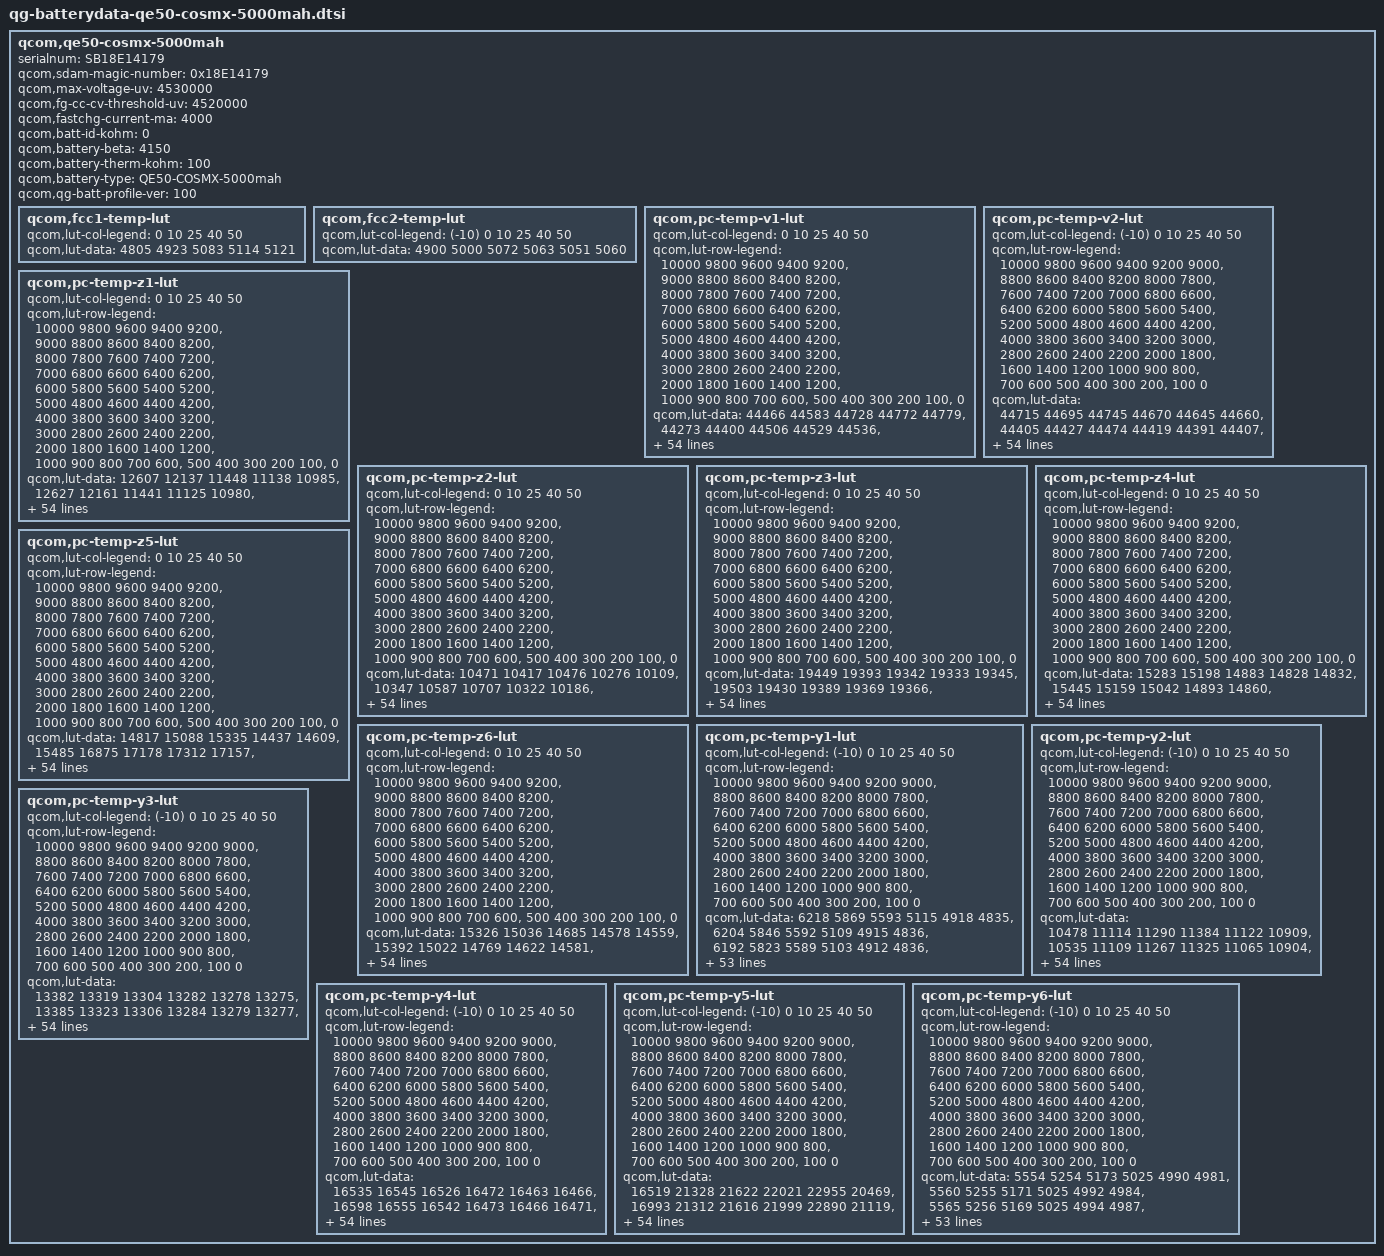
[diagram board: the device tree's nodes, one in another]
/* Copyright (c) 2018, The Linux Foundation. All rights reserved.
 *
 * This program is free software; you can redistribute it and/or modify
 * it under the terms of the GNU General Public License version 2 and
 * only version 2 as published by the Free Software Foundation.
 *
 * This program is distributed in the hope that it will be useful,
 * but WITHOUT ANY WARRANTY; without even the implied warranty of
 * MERCHANTABILITY or FITNESS FOR A PARTICULAR PURPOSE.  See the
 * GNU General Public License for more details.
 */
qcom,qe50-cosmx-5000mah {
    /* 6988537_Huaqin_QN6982A_COSMX_5000mAH_PM7250B_averaged_MasterSlave_Feb12th2024 */
    serialnum = "SB18E14179";
    qcom,sdam-magic-number = <0x18E14179>;
    qcom,max-voltage-uv = <4530000>;
    qcom,fg-cc-cv-threshold-uv = <4520000>;
    qcom,fastchg-current-ma = <4000>;
    qcom,batt-id-kohm = <0>;
    qcom,battery-beta = <4150>;
    qcom,battery-therm-kohm = <100>;
    qcom,battery-type = "QE50-COSMX-5000mah";
    qcom,qg-batt-profile-ver = <100>;

	qcom,fcc1-temp-lut {
		qcom,lut-col-legend = <0 10 25 40 50>;
		qcom,lut-data = <4805 4923 5083 5114 5121>;
	};

	qcom,fcc2-temp-lut {
		qcom,lut-col-legend = <(-10) 0 10 25 40 50>;
		qcom,lut-data = <4900 5000 5072 5063 5051 5060>;
	};

	qcom,pc-temp-v1-lut {
		qcom,lut-col-legend = <0 10 25 40 50>;
		qcom,lut-row-legend = <10000 9800 9600 9400 9200>,
			<9000 8800 8600 8400 8200>,
			<8000 7800 7600 7400 7200>,
			<7000 6800 6600 6400 6200>,
			<6000 5800 5600 5400 5200>,
			<5000 4800 4600 4400 4200>,
			<4000 3800 3600 3400 3200>,
			<3000 2800 2600 2400 2200>,
			<2000 1800 1600 1400 1200>,
			<1000 900 800 700 600>,
			<500 400 300 200 100>,
			<0>;
		qcom,lut-data = <44466 44583 44728 44772 44779>,
			<44273 44400 44506 44529 44536>,
			<44081 44215 44321 44338 44339>,
			<43884 44029 44142 44157 44160>,
			<43678 43837 43950 43967 43971>,
			<43463 43632 43749 43767 43770>,
			<43239 43415 43536 43558 43562>,
			<43004 43189 43309 43337 43343>,
			<42764 42953 43073 43106 43114>,
			<42524 42711 42829 42866 42877>,
			<42282 42470 42578 42616 42630>,
			<42044 42229 42328 42365 42381>,
			<41813 41988 42079 42114 42132>,
			<41586 41747 41834 41864 41883>,
			<41364 41511 41593 41621 41640>,
			<41146 41285 41357 41382 41400>,
			<40934 41065 41129 41150 41168>,
			<40729 40856 40908 40927 40943>,
			<40532 40663 40698 40712 40726>,
			<40337 40477 40507 40513 40522>,
			<40153 40271 40322 40323 40330>,
			<39962 40024 40095 40099 40110>,
			<39731 39761 39796 39801 39826>,
			<39451 39496 39523 39527 39561>,
			<39217 39256 39328 39353 39384>,
			<39061 39100 39168 39215 39242>,
			<38935 38992 39039 39075 39097>,
			<38830 38896 38929 38929 38944>,
			<38740 38795 38826 38798 38807>,
			<38660 38696 38725 38692 38695>,
			<38582 38603 38630 38599 38597>,
			<38509 38516 38539 38511 38505>,
			<38441 38434 38451 38428 38420>,
			<38378 38360 38370 38350 38340>,
			<38321 38292 38298 38279 38266>,
			<38272 38231 38230 38210 38193>,
			<38231 38180 38163 38138 38117>,
			<38184 38128 38099 38061 38039>,
			<38118 38061 38022 37969 37944>,
			<38036 37978 37922 37842 37811>,
			<37936 37879 37809 37704 37664>,
			<37810 37755 37685 37582 37529>,
			<37667 37613 37545 37457 37394>,
			<37503 37449 37376 37284 37213>,
			<37337 37290 37224 37144 37072>,
			<37208 37162 37120 37064 37005>,
			<37171 37119 37087 37033 36980>,
			<37128 37090 37062 37010 36955>,
			<37092 37057 37040 36985 36927>,
			<37055 37015 36986 36914 36853>,
			<36969 36864 36749 36627 36557>,
			<36666 36563 36297 36166 36104>,
			<36146 36051 35700 35563 35512>,
			<35447 35325 34888 34736 34700>,
			<34308 34189 33628 33437 33444>,
			<30000 30000 30000 30000 30000>;
	};

	qcom,pc-temp-v2-lut {
		qcom,lut-col-legend = <(-10) 0 10 25 40 50>;
		qcom,lut-row-legend = <10000 9800 9600 9400 9200 9000>,
			<8800 8600 8400 8200 8000 7800>,
			<7600 7400 7200 7000 6800 6600>,
			<6400 6200 6000 5800 5600 5400>,
			<5200 5000 4800 4600 4400 4200>,
			<4000 3800 3600 3400 3200 3000>,
			<2800 2600 2400 2200 2000 1800>,
			<1600 1400 1200 1000 900 800>,
			<700 600 500 400 300 200>,
			<100 0>;
		qcom,lut-data = <44715 44695 44745 44670 44645 44660>,
			<44405 44427 44474 44419 44391 44407>,
			<44130 44181 44229 44184 44153 44172>,
			<43894 43963 44017 43968 43936 43959>,
			<43697 43771 43836 43769 43739 43769>,
			<43504 43575 43649 43566 43537 43573>,
			<43294 43363 43442 43348 43321 43360>,
			<43078 43141 43223 43121 43096 43137>,
			<42855 42909 42995 42886 42863 42905>,
			<42622 42665 42755 42640 42619 42662>,
			<42387 42419 42512 42391 42372 42415>,
			<42153 42174 42267 42142 42125 42166>,
			<41919 41930 42020 41891 41877 41916>,
			<41679 41692 41776 41646 41633 41671>,
			<41433 41458 41534 41405 41394 41431>,
			<41182 41228 41298 41170 41160 41197>,
			<40920 41009 41069 40941 40933 40968>,
			<40648 40789 40847 40720 40714 40748>,
			<40382 40539 40638 40512 40509 40539>,
			<40124 40254 40434 40314 40314 40339>,
			<39877 39975 40197 40094 40107 40133>,
			<39647 39715 39901 39834 39878 39921>,
			<39432 39472 39611 39572 39642 39701>,
			<39232 39262 39374 39338 39403 39456>,
			<39045 39078 39168 39122 39163 39201>,
			<38872 38913 38990 38944 38970 39002>,
			<38715 38762 38834 38801 38821 38854>,
			<38571 38624 38694 38674 38692 38726>,
			<38437 38497 38563 38553 38574 38602>,
			<38307 38379 38444 38441 38468 38489>,
			<38185 38270 38337 38338 38371 38386>,
			<38087 38166 38237 38242 38283 38294>,
			<38008 38070 38142 38154 38199 38207>,
			<37937 37984 38051 38075 38115 38124>,
			<37866 37908 37964 38000 38032 38041>,
			<37798 37839 37884 37920 37939 37942>,
			<37728 37778 37813 37834 37836 37820>,
			<37657 37720 37741 37743 37728 37699>,
			<37582 37652 37666 37644 37627 37594>,
			<37496 37575 37585 37538 37525 37492>,
			<37401 37483 37487 37435 37422 37388>,
			<37303 37361 37371 37330 37317 37279>,
			<37202 37217 37229 37196 37184 37133>,
			<37104 37056 37076 37042 37025 36968>,
			<37012 36918 36928 36932 36928 36878>,
			<36919 36812 36823 36880 36877 36826>,
			<36870 36764 36782 36866 36864 36812>,
			<36822 36721 36740 36847 36847 36794>,
			<36775 36674 36678 36808 36818 36763>,
			<36721 36612 36561 36685 36735 36665>,
			<36653 36485 36324 36340 36427 36332>,
			<36569 36143 35924 35797 35929 35826>,
			<36457 35526 35311 35071 35276 35159>,
			<36069 34533 34461 34019 34366 34223>,
			<35516 33478 33260 32501 32956 32853>,
			<35225 31991 29998 28746 28131 29180>;
	};

	qcom,pc-temp-z1-lut {
		qcom,lut-col-legend = <0 10 25 40 50>;
		qcom,lut-row-legend = <10000 9800 9600 9400 9200>,
			<9000 8800 8600 8400 8200>,
			<8000 7800 7600 7400 7200>,
			<7000 6800 6600 6400 6200>,
			<6000 5800 5600 5400 5200>,
			<5000 4800 4600 4400 4200>,
			<4000 3800 3600 3400 3200>,
			<3000 2800 2600 2400 2200>,
			<2000 1800 1600 1400 1200>,
			<1000 900 800 700 600>,
			<500 400 300 200 100>,
			<0>;
		qcom,lut-data = <12607 12137 11448 11138 10985>,
			<12627 12161 11441 11125 10980>,
			<12638 12164 11428 11113 10972>,
			<12644 12144 11418 11101 10964>,
			<12633 12119 11405 11090 10956>,
			<12600 12105 11391 11079 10948>,
			<12570 12096 11376 11069 10940>,
			<12540 12083 11361 11060 10934>,
			<12511 12059 11346 11052 10928>,
			<12496 12035 11333 11045 10924>,
			<12483 12018 11322 11040 10921>,
			<12470 12006 11315 11036 10918>,
			<12452 11997 11311 11033 10916>,
			<12431 11993 11308 11030 10914>,
			<12415 11990 11307 11029 10913>,
			<12402 11987 11307 11028 10913>,
			<12394 11983 11307 11027 10912>,
			<12395 11980 11307 11030 10912>,
			<12401 11981 11307 11033 10912>,
			<12407 11984 11310 11032 10912>,
			<12419 11985 11314 11029 10913>,
			<12430 11986 11314 11028 10913>,
			<12434 11986 11312 11027 10912>,
			<12434 11988 11311 11026 10911>,
			<12433 11993 11312 11026 10911>,
			<12431 11999 11316 11028 10913>,
			<12427 12007 11320 11030 10914>,
			<12429 12013 11329 11033 10916>,
			<12435 12014 11336 11036 10918>,
			<12441 12015 11341 11039 10920>,
			<12448 12018 11345 11042 10923>,
			<12459 12027 11349 11046 10926>,
			<12468 12036 11354 11049 10930>,
			<12476 12041 11361 11054 10933>,
			<12484 12045 11369 11059 10937>,
			<12487 12050 11379 11065 10941>,
			<12485 12062 11388 11071 10945>,
			<12485 12074 11397 11078 10950>,
			<12497 12083 11406 11084 10955>,
			<12516 12090 11416 11091 10959>,
			<12537 12099 11424 11097 10964>,
			<12563 12112 11434 11103 10968>,
			<12572 12123 11443 11108 10973>,
			<12564 12120 11453 11113 10977>,
			<12585 12133 11464 11120 10981>,
			<12604 12149 11468 11124 10984>,
			<12600 12164 11476 11124 10984>,
			<12585 12158 11480 11124 10984>,
			<12600 12160 11491 11129 10988>,
			<12595 12168 11489 11137 10993>,
			<12635 12163 11489 11142 10997>,
			<12627 12185 11495 11146 11002>,
			<12649 12192 11517 11157 11011>,
			<12658 12216 11526 11169 11022>,
			<12658 12216 11526 11169 11022>,
			<12658 12216 11526 11169 11022>;
	};

	qcom,pc-temp-z2-lut {
		qcom,lut-col-legend = <0 10 25 40 50>;
		qcom,lut-row-legend = <10000 9800 9600 9400 9200>,
			<9000 8800 8600 8400 8200>,
			<8000 7800 7600 7400 7200>,
			<7000 6800 6600 6400 6200>,
			<6000 5800 5600 5400 5200>,
			<5000 4800 4600 4400 4200>,
			<4000 3800 3600 3400 3200>,
			<3000 2800 2600 2400 2200>,
			<2000 1800 1600 1400 1200>,
			<1000 900 800 700 600>,
			<500 400 300 200 100>,
			<0>;
		qcom,lut-data = <10471 10417 10476 10276 10109>,
			<10347 10587 10707 10322 10186>,
			<10430 10650 10721 10488 10390>,
			<10503 10643 10716 10564 10487>,
			<10496 10615 10685 10572 10502>,
			<10463 10577 10615 10514 10453>,
			<10431 10536 10548 10440 10385>,
			<10402 10504 10484 10365 10311>,
			<10374 10467 10426 10293 10236>,
			<10353 10434 10391 10265 10202>,
			<10334 10562 10366 10251 10185>,
			<10320 10809 10358 10247 10176>,
			<10309 10845 10355 10258 10175>,
			<10300 10612 10354 10274 10177>,
			<10300 10419 10356 10277 10173>,
			<10315 10420 10362 10265 10166>,
			<10334 10427 10371 10260 10160>,
			<10344 10449 10387 10278 10135>,
			<10352 10698 10411 10298 10106>,
			<10363 10953 10676 10276 10115>,
			<10378 10888 11224 10215 10147>,
			<10398 10642 12118 10203 10165>,
			<10427 10542 13715 10308 10171>,
			<10472 10540 14442 10399 10178>,
			<10497 10513 12658 10340 10190>,
			<10494 10494 10447 10219 10212>,
			<10488 10480 10208 10286 10299>,
			<10480 10472 10249 10959 10724>,
			<10467 10477 10296 11434 11029>,
			<10457 10485 10344 11221 10872>,
			<10453 10487 10394 10825 10562>,
			<10451 10484 10443 10609 10375>,
			<10451 10480 10504 10480 10250>,
			<10457 10485 10527 10361 10153>,
			<10465 10500 10495 10208 10062>,
			<10466 10510 10459 10093 9999>,
			<10465 10512 10457 10092 10009>,
			<10463 10515 10461 10134 10077>,
			<10466 10519 10471 10186 10150>,
			<10469 10526 10513 10262 10226>,
			<10466 10533 10558 10330 10290>,
			<10446 10538 10580 10361 10316>,
			<10423 10540 10595 10392 10335>,
			<10399 10516 10603 10534 10463>,
			<10496 10551 10588 10553 10484>,
			<10507 10553 10525 10336 10263>,
			<10473 10543 10460 10326 10220>,
			<10468 10536 10456 10332 10239>,
			<10472 10546 10461 10360 10239>,
			<10404 10592 10548 10420 10319>,
			<10379 10573 10535 10347 10282>,
			<10255 10541 10474 10135 10006>,
			<10112 10356 10394 10049 9942>,
			<9981 10323 10301 9982 9890>,
			<9981 10323 10301 9982 9890>,
			<9981 10323 10301 9982 9890>;
	};

	qcom,pc-temp-z3-lut {
		qcom,lut-col-legend = <0 10 25 40 50>;
		qcom,lut-row-legend = <10000 9800 9600 9400 9200>,
			<9000 8800 8600 8400 8200>,
			<8000 7800 7600 7400 7200>,
			<7000 6800 6600 6400 6200>,
			<6000 5800 5600 5400 5200>,
			<5000 4800 4600 4400 4200>,
			<4000 3800 3600 3400 3200>,
			<3000 2800 2600 2400 2200>,
			<2000 1800 1600 1400 1200>,
			<1000 900 800 700 600>,
			<500 400 300 200 100>,
			<0>;
		qcom,lut-data = <19449 19393 19342 19333 19345>,
			<19503 19430 19389 19369 19366>,
			<19526 19450 19402 19387 19390>,
			<19541 19458 19409 19398 19397>,
			<19551 19462 19417 19408 19404>,
			<19559 19466 19425 19417 19414>,
			<19562 19469 19432 19422 19419>,
			<19563 19471 19438 19424 19420>,
			<19563 19470 19441 19425 19421>,
			<19562 19469 19440 19424 19420>,
			<19560 19474 19437 19419 19415>,
			<19557 19481 19433 19415 19410>,
			<19551 19481 19426 19411 19406>,
			<19543 19468 19418 19408 19403>,
			<19537 19455 19413 19404 19399>,
			<19531 19450 19410 19400 19395>,
			<19527 19447 19405 19395 19391>,
			<19523 19446 19401 19390 19386>,
			<19519 19447 19398 19384 19381>,
			<19516 19448 19395 19378 19376>,
			<19514 19446 19392 19373 19370>,
			<19512 19448 19390 19370 19366>,
			<19516 19454 19390 19370 19363>,
			<19531 19455 19391 19370 19360>,
			<19541 19452 19384 19360 19351>,
			<19539 19446 19372 19342 19340>,
			<19534 19439 19368 19346 19345>,
			<19529 19435 19367 19407 19404>,
			<19525 19435 19367 19450 19448>,
			<19521 19437 19369 19445 19444>,
			<19519 19439 19374 19434 19434>,
			<19517 19442 19381 19424 19424>,
			<19517 19445 19394 19415 19414>,
			<19517 19446 19400 19405 19404>,
			<19518 19446 19398 19391 19392>,
			<19517 19446 19395 19378 19379>,
			<19515 19443 19391 19367 19368>,
			<19513 19440 19383 19358 19358>,
			<19510 19436 19378 19355 19350>,
			<19506 19432 19377 19355 19345>,
			<19502 19429 19376 19356 19342>,
			<19498 19426 19373 19357 19347>,
			<19493 19423 19370 19357 19360>,
			<19485 19420 19369 19363 19367>,
			<19450 19407 19365 19363 19368>,
			<19419 19401 19356 19349 19358>,
			<19353 19396 19350 19341 19347>,
			<19348 19366 19348 19331 19332>,
			<19323 19359 19340 19328 19325>,
			<19294 19335 19333 19325 19323>,
			<19296 19336 19343 19338 19331>,
			<19306 19337 19363 19365 19356>,
			<19348 19366 19371 19366 19356>,
			<19402 19387 19372 19367 19356>,
			<19402 19387 19372 19367 19356>,
			<19402 19387 19372 19367 19356>;
	};

	qcom,pc-temp-z4-lut {
		qcom,lut-col-legend = <0 10 25 40 50>;
		qcom,lut-row-legend = <10000 9800 9600 9400 9200>,
			<9000 8800 8600 8400 8200>,
			<8000 7800 7600 7400 7200>,
			<7000 6800 6600 6400 6200>,
			<6000 5800 5600 5400 5200>,
			<5000 4800 4600 4400 4200>,
			<4000 3800 3600 3400 3200>,
			<3000 2800 2600 2400 2200>,
			<2000 1800 1600 1400 1200>,
			<1000 900 800 700 600>,
			<500 400 300 200 100>,
			<0>;
		qcom,lut-data = <15283 15198 14883 14828 14832>,
			<15445 15159 15042 14893 14860>,
			<15336 15106 15012 14900 14881>,
			<15201 15032 14952 14871 14860>,
			<15110 14961 14908 14845 14840>,
			<15030 14907 14870 14821 14823>,
			<14967 14863 14836 14799 14805>,
			<14917 14829 14806 14779 14787>,
			<14876 14802 14780 14762 14769>,
			<14842 14777 14757 14749 14759>,
			<14813 14743 14737 14739 14753>,
			<14789 14707 14726 14732 14750>,
			<14771 14694 14721 14729 14748>,
			<14756 14702 14716 14726 14746>,
			<14744 14708 14711 14722 14744>,
			<14734 14706 14705 14719 14742>,
			<14727 14703 14700 14716 14739>,
			<14723 14698 14697 14713 14738>,
			<14720 14683 14693 14710 14736>,
			<14718 14668 14680 14706 14733>,
			<14716 14669 14667 14701 14728>,
			<14715 14698 14674 14705 14730>,
			<14727 14738 14737 14769 14788>,
			<14778 14786 14799 14831 14846>,
			<14811 14831 14832 14846 14853>,
			<14813 14838 14855 14854 14855>,
			<14814 14823 14855 14845 14845>,
			<14813 14803 14841 14770 14775>,
			<14802 14785 14823 14713 14720>,
			<14787 14768 14805 14708 14715>,
			<14777 14752 14785 14705 14713>,
			<14768 14738 14763 14702 14709>,
			<14761 14727 14738 14697 14705>,
			<14756 14719 14720 14693 14700>,
			<14751 14714 14707 14688 14693>,
			<14745 14710 14698 14683 14685>,
			<14738 14707 14693 14679 14680>,
			<14731 14704 14689 14674 14676>,
			<14723 14702 14689 14674 14676>,
			<14714 14700 14694 14690 14698>,
			<14706 14697 14700 14706 14721>,
			<14699 14692 14700 14703 14715>,
			<14691 14683 14698 14695 14700>,
			<14681 14673 14697 14698 14706>,
			<14670 14655 14686 14691 14702>,
			<14694 14650 14668 14669 14666>,
			<14761 14648 14665 14670 14667>,
			<14766 14672 14652 14661 14663>,
			<14791 14670 14638 14637 14640>,
			<14819 14690 14633 14623 14622>,
			<14812 14692 14650 14664 14680>,
			<14810 14699 14656 14668 14692>,
			<14785 14685 14657 14677 14703>,
			<14758 14683 14662 14684 14712>,
			<14758 14683 14662 14684 14712>,
			<14758 14683 14662 14684 14712>;
	};

	qcom,pc-temp-z5-lut {
		qcom,lut-col-legend = <0 10 25 40 50>;
		qcom,lut-row-legend = <10000 9800 9600 9400 9200>,
			<9000 8800 8600 8400 8200>,
			<8000 7800 7600 7400 7200>,
			<7000 6800 6600 6400 6200>,
			<6000 5800 5600 5400 5200>,
			<5000 4800 4600 4400 4200>,
			<4000 3800 3600 3400 3200>,
			<3000 2800 2600 2400 2200>,
			<2000 1800 1600 1400 1200>,
			<1000 900 800 700 600>,
			<500 400 300 200 100>,
			<0>;
		qcom,lut-data = <14817 15088 15335 14437 14609>,
			<15485 16875 17178 17312 17157>,
			<16266 18009 17763 18654 19669>,
			<17073 18616 18261 19938 20936>,
			<17857 19094 18813 21207 22267>,
			<18655 19682 19482 22432 23768>,
			<19472 20439 20319 23534 25059>,
			<20292 21181 21400 24471 26102>,
			<21141 21768 22617 25340 27018>,
			<22115 22456 24153 26272 27614>,
			<23289 25422 25868 27272 28006>,
			<24251 29985 26458 28170 28338>,
			<24794 31297 26490 28863 28629>,
			<25257 29376 26531 29526 28922>,
			<25984 27774 27053 30393 29367>,
			<27235 28268 28346 31451 30021>,
			<28481 29254 29565 32488 30715>,
			<29256 30374 30774 33469 31363>,
			<29862 32958 31989 34449 32088>,
			<30680 35326 33730 35595 33238>,
			<31786 35341 35302 36790 34728>,
			<33480 41278 35500 37032 35074>,
			<38622 49089 37796 35323 32487>,
			<51557 48772 39178 32403 28483>,
			<59272 41972 33601 26588 23503>,
			<55243 35902 24679 18874 17940>,
			<47496 30271 21199 18971 18316>,
			<42336 26730 19802 32349 31989>,
			<38562 26442 19326 41815 42219>,
			<36244 26597 19430 40756 42060>,
			<35709 27159 19715 38798 41613>,
			<35410 29274 20941 37920 41388>,
			<35359 32188 24640 37501 41081>,
			<36283 35170 28195 36930 40550>,
			<37726 38443 31250 34233 38963>,
			<38807 40377 33677 31343 36753>,
			<39727 41375 34802 31104 34938>,
			<40801 41926 35504 31333 33156>,
			<42710 41871 36063 31834 31558>,
			<44729 41632 36620 34984 29886>,
			<44970 41518 36945 38039 28780>,
			<42884 40866 34384 34873 28970>,
			<40080 40302 29925 28676 29944>,
			<36186 40736 30356 32586 34915>,
			<30613 40845 30602 34172 38142>,
			<25492 38260 28669 26302 31802>,
			<13773 34698 25727 21800 22975>,
			<13416 22870 26656 20025 18837>,
			<12532 20683 25316 23388 21310>,
			<11879 14950 24071 28332 29982>,
			<11982 15095 26102 26005 24195>,
			<12273 15255 24973 24282 20415>,
			<13051 18307 25188 20904 17432>,
			<15578 22175 22455 17955 15234>,
			<15578 22175 22455 17955 15234>,
			<15578 22175 22455 17955 15234>;
	};

	qcom,pc-temp-z6-lut {
		qcom,lut-col-legend = <0 10 25 40 50>;
		qcom,lut-row-legend = <10000 9800 9600 9400 9200>,
			<9000 8800 8600 8400 8200>,
			<8000 7800 7600 7400 7200>,
			<7000 6800 6600 6400 6200>,
			<6000 5800 5600 5400 5200>,
			<5000 4800 4600 4400 4200>,
			<4000 3800 3600 3400 3200>,
			<3000 2800 2600 2400 2200>,
			<2000 1800 1600 1400 1200>,
			<1000 900 800 700 600>,
			<500 400 300 200 100>,
			<0>;
		qcom,lut-data = <15326 15036 14685 14578 14559>,
			<15392 15022 14769 14622 14581>,
			<15333 14998 14756 14629 14598>,
			<15259 14960 14730 14622 14594>,
			<15205 14919 14710 14615 14590>,
			<15156 14888 14694 14608 14586>,
			<15114 14862 14679 14601 14581>,
			<15079 14840 14666 14593 14575>,
			<15048 14820 14653 14584 14567>,
			<15021 14802 14640 14577 14561>,
			<14996 14786 14628 14569 14555>,
			<14975 14770 14618 14563 14550>,
			<14955 14760 14610 14559 14547>,
			<14938 14753 14604 14555 14544>,
			<14925 14748 14598 14551 14540>,
			<14915 14744 14593 14546 14536>,
			<14908 14740 14589 14542 14532>,
			<14904 14736 14585 14537 14528>,
			<14901 14731 14581 14533 14524>,
			<14900 14726 14575 14527 14519>,
			<14901 14726 14569 14522 14514>,
			<14901 14740 14572 14522 14513>,
			<14910 14759 14602 14551 14536>,
			<14940 14779 14628 14577 14558>,
			<14960 14798 14636 14575 14557>,
			<14961 14800 14639 14571 14553>,
			<14961 14792 14636 14570 14552>,
			<14961 14782 14631 14571 14553>,
			<14956 14776 14626 14571 14554>,
			<14950 14771 14621 14568 14551>,
			<14946 14768 14615 14560 14545>,
			<14944 14765 14612 14554 14539>,
			<14943 14763 14609 14548 14533>,
			<14944 14763 14606 14542 14526>,
			<14945 14763 14602 14533 14517>,
			<14945 14763 14598 14525 14508>,
			<14945 14763 14594 14518 14500>,
			<14946 14763 14591 14512 14492>,
			<14947 14764 14590 14510 14489>,
			<14949 14765 14593 14518 14495>,
			<14951 14766 14597 14526 14502>,
			<14954 14767 14598 14525 14504>,
			<14958 14767 14598 14523 14505>,
			<14962 14766 14600 14528 14511>,
			<14955 14761 14597 14526 14511>,
			<14955 14759 14587 14510 14490>,
			<14951 14757 14584 14507 14485>,
			<14951 14753 14579 14498 14476>,
			<14954 14750 14570 14486 14463>,
			<14953 14752 14567 14479 14454>,
			<14958 14757 14580 14504 14483>,
			<14975 14767 14596 14523 14506>,
			<14993 14784 14605 14530 14515>,
			<15020 14804 14613 14538 14523>,
			<15020 14804 14613 14538 14523>,
			<15020 14804 14613 14538 14523>;
	};

	qcom,pc-temp-y1-lut {
		qcom,lut-col-legend = <(-10) 0 10 25 40 50>;
		qcom,lut-row-legend = <10000 9800 9600 9400 9200 9000>,
			<8800 8600 8400 8200 8000 7800>,
			<7600 7400 7200 7000 6800 6600>,
			<6400 6200 6000 5800 5600 5400>,
			<5200 5000 4800 4600 4400 4200>,
			<4000 3800 3600 3400 3200 3000>,
			<2800 2600 2400 2200 2000 1800>,
			<1600 1400 1200 1000 900 800>,
			<700 600 500 400 300 200>,
			<100 0>;
		qcom,lut-data = <6218 5869 5593 5115 4918 4835>,
			<6204 5846 5592 5109 4915 4836>,
			<6192 5823 5589 5103 4912 4836>,
			<6182 5801 5586 5098 4909 4835>,
			<6175 5785 5582 5092 4907 4833>,
			<6172 5777 5578 5088 4905 4831>,
			<6178 5778 5573 5084 4903 4827>,
			<6190 5781 5566 5080 4902 4823>,
			<6193 5780 5559 5076 4900 4821>,
			<6183 5772 5550 5073 4897 4820>,
			<6175 5767 5545 5070 4895 4820>,
			<6178 5765 5540 5068 4894 4819>,
			<6186 5763 5534 5067 4893 4818>,
			<6189 5762 5528 5065 4892 4817>,
			<6185 5767 5520 5063 4890 4816>,
			<6181 5769 5518 5061 4889 4815>,
			<6178 5766 5517 5061 4889 4815>,
			<6174 5762 5517 5061 4889 4814>,
			<6173 5763 5518 5061 4889 4814>,
			<6176 5766 5517 5062 4890 4815>,
			<6179 5769 5516 5062 4891 4815>,
			<6179 5774 5516 5064 4891 4816>,
			<6175 5778 5515 5065 4891 4817>,
			<6173 5778 5514 5067 4892 4817>,
			<6172 5774 5514 5070 4894 4818>,
			<6173 5772 5516 5073 4896 4819>,
			<6178 5777 5524 5076 4897 4820>,
			<6199 5784 5530 5078 4899 4821>,
			<6213 5784 5530 5080 4901 4823>,
			<6202 5779 5526 5082 4903 4824>,
			<6183 5776 5525 5085 4906 4826>,
			<6181 5779 5529 5088 4909 4828>,
			<6191 5783 5532 5091 4911 4830>,
			<6198 5786 5534 5095 4914 4832>,
			<6197 5785 5537 5099 4916 4834>,
			<6196 5785 5539 5103 4918 4836>,
			<6196 5790 5542 5108 4920 4837>,
			<6200 5798 5545 5112 4922 4839>,
			<6204 5802 5547 5114 4923 4840>,
			<6195 5804 5549 5116 4925 4842>,
			<6171 5806 5553 5118 4927 4842>,
			<6159 5800 5560 5123 4929 4843>,
			<6157 5796 5568 5127 4931 4844>,
			<6157 5790 5575 5132 4934 4848>,
			<6170 5786 5572 5135 4938 4851>,
			<6189 5803 5583 5140 4941 4853>,
			<6190 5820 5584 5142 4940 4852>,
			<6181 5809 5587 5143 4940 4852>,
			<6172 5802 5586 5143 4941 4854>,
			<6224 5797 5587 5141 4940 4855>,
			<6251 5857 5589 5145 4941 4856>,
			<6341 5932 5601 5151 4947 4860>,
			<6450 6137 5646 5166 4953 4866>,
			<6598 6252 5815 5179 4961 4875>,
			<6598 6252 5815 5179 4961 4875>,
			<6598 6252 5815 5179 4961 4875>;
	};

	qcom,pc-temp-y2-lut {
		qcom,lut-col-legend = <(-10) 0 10 25 40 50>;
		qcom,lut-row-legend = <10000 9800 9600 9400 9200 9000>,
			<8800 8600 8400 8200 8000 7800>,
			<7600 7400 7200 7000 6800 6600>,
			<6400 6200 6000 5800 5600 5400>,
			<5200 5000 4800 4600 4400 4200>,
			<4000 3800 3600 3400 3200 3000>,
			<2800 2600 2400 2200 2000 1800>,
			<1600 1400 1200 1000 900 800>,
			<700 600 500 400 300 200>,
			<100 0>;
		qcom,lut-data = <10478 11114 11290 11384 11122 10909>,
			<10535 11109 11267 11325 11065 10904>,
			<10606 11098 11241 11239 10991 10889>,
			<10679 11083 11211 11145 10915 10867>,
			<10740 11067 11180 11067 10852 10838>,
			<10778 11056 11147 11027 10815 10806>,
			<10792 11037 11105 11014 10798 10764>,
			<10800 11014 11067 11003 10784 10720>,
			<10811 11009 11050 10989 10765 10690>,
			<10824 11014 11039 10972 10737 10668>,
			<10839 11021 11036 10964 10711 10647>,
			<10863 11034 11042 10960 10687 10618>,
			<10895 11056 11052 10957 10668 10596>,
			<10923 11081 11066 10965 10675 10594>,
			<10951 11112 11095 10984 10713 10596>,
			<10973 11149 11133 11011 10752 10599>,
			<10981 11208 11186 11062 10781 10611>,
			<10986 11268 11249 11134 10816 10633>,
			<10987 11269 11326 11236 10875 10665>,
			<10981 11217 11413 11370 10972 10722>,
			<10971 11185 11432 11416 11078 10817>,
			<10965 11188 11341 11374 11228 11103>,
			<10961 11196 11260 11312 11341 11349>,
			<10954 11202 11256 11256 11280 11265>,
			<10941 11207 11265 11198 11098 11025>,
			<10923 11212 11274 11189 11031 10945>,
			<10908 11223 11284 11256 11047 10987>,
			<10895 11238 11288 11316 11074 11046>,
			<10873 11244 11286 11308 11118 11089>,
			<10603 11248 11290 11287 11180 11132>,
			<10133 11250 11309 11288 11204 11187>,
			<9921 11241 11340 11351 11194 11295>,
			<9834 11223 11351 11421 11185 11403>,
			<9779 11210 11330 11463 11256 11519>,
			<9748 11187 11313 11494 11406 11647>,
			<9727 11161 11312 11511 11446 11638>,
			<9712 11124 11304 11531 11389 11424>,
			<9700 11065 11283 11539 11318 11258>,
			<9692 10992 11225 11475 11257 11232>,
			<9684 10902 11165 11367 11202 11219>,
			<9678 10796 11127 11356 11198 11200>,
			<9673 10634 11082 11407 11238 11170>,
			<9670 10391 10956 11358 11223 11092>,
			<9667 9938 10831 11202 11062 10910>,
			<9663 9745 10613 11143 10904 10727>,
			<9660 9696 10357 11168 10827 10648>,
			<9658 9679 10267 11253 10886 10635>,
			<9657 9668 10165 11273 10884 10656>,
			<9655 9660 10027 11308 10920 10695>,
			<9652 9654 9893 11292 10920 10715>,
			<9650 9650 9778 11166 10778 10616>,
			<9648 9649 9684 11056 10722 10584>,
			<9648 9648 9659 10941 10627 10521>,
			<9648 9649 9656 10765 10509 10349>,
			<9648 9649 9656 10765 10509 10349>,
			<9648 9649 9656 10765 10509 10349>;
	};

	qcom,pc-temp-y3-lut {
		qcom,lut-col-legend = <(-10) 0 10 25 40 50>;
		qcom,lut-row-legend = <10000 9800 9600 9400 9200 9000>,
			<8800 8600 8400 8200 8000 7800>,
			<7600 7400 7200 7000 6800 6600>,
			<6400 6200 6000 5800 5600 5400>,
			<5200 5000 4800 4600 4400 4200>,
			<4000 3800 3600 3400 3200 3000>,
			<2800 2600 2400 2200 2000 1800>,
			<1600 1400 1200 1000 900 800>,
			<700 600 500 400 300 200>,
			<100 0>;
		qcom,lut-data = <13382 13319 13304 13282 13278 13275>,
			<13385 13323 13306 13284 13279 13277>,
			<13390 13328 13308 13285 13281 13279>,
			<13396 13331 13310 13287 13282 13281>,
			<13402 13335 13312 13288 13283 13283>,
			<13404 13337 13313 13290 13285 13284>,
			<13405 13339 13314 13291 13286 13285>,
			<13405 13340 13315 13292 13287 13286>,
			<13405 13340 13316 13293 13288 13287>,
			<13405 13340 13317 13295 13289 13288>,
			<13405 13339 13318 13296 13290 13289>,
			<13405 13338 13318 13296 13291 13289>,
			<13405 13337 13318 13297 13292 13290>,
			<13405 13337 13318 13297 13293 13291>,
			<13403 13336 13317 13298 13293 13291>,
			<13400 13336 13316 13298 13294 13292>,
			<13396 13337 13314 13299 13295 13294>,
			<13389 13339 13313 13299 13296 13295>,
			<13383 13339 13313 13298 13297 13296>,
			<13378 13334 13314 13296 13298 13297>,
			<13374 13329 13314 13294 13299 13298>,
			<13370 13325 13310 13292 13295 13295>,
			<13367 13322 13305 13291 13290 13291>,
			<13364 13320 13302 13289 13286 13287>,
			<13361 13318 13301 13286 13284 13283>,
			<13358 13317 13300 13285 13282 13282>,
			<13356 13316 13299 13285 13280 13284>,
			<13355 13316 13298 13285 13280 13285>,
			<13353 13315 13298 13284 13279 13285>,
			<13347 13315 13297 13283 13279 13284>,
			<13339 13315 13298 13283 13279 13283>,
			<13338 13314 13298 13283 13279 13282>,
			<13344 13313 13298 13283 13279 13281>,
			<13353 13313 13297 13283 13280 13282>,
			<13361 13314 13296 13284 13281 13285>,
			<13371 13314 13296 13284 13282 13285>,
			<13384 13315 13296 13285 13281 13283>,
			<13403 13317 13297 13285 13281 13282>,
			<13426 13319 13297 13284 13281 13282>,
			<13454 13322 13298 13283 13282 13284>,
			<13488 13326 13299 13283 13283 13284>,
			<13533 13329 13300 13284 13283 13284>,
			<13595 13332 13301 13283 13283 13283>,
			<13687 13341 13304 13281 13279 13279>,
			<13849 13363 13303 13282 13282 13283>,
			<14109 13402 13305 13287 13288 13288>,
			<14283 13447 13311 13293 13291 13290>,
			<14512 13563 13325 13296 13292 13291>,
			<14999 13844 13345 13298 13294 13293>,
			<16151 14827 13393 13298 13293 13293>,
			<18773 17937 13544 13294 13288 13290>,
			<25383 27294 14228 13295 13289 13294>,
			<44088 64563 17411 13300 13294 13296>,
			<65535 65535 28778 13311 13301 13302>,
			<65535 65535 28778 13311 13301 13302>,
			<65535 65535 28778 13311 13301 13302>;
	};

	qcom,pc-temp-y4-lut {
		qcom,lut-col-legend = <(-10) 0 10 25 40 50>;
		qcom,lut-row-legend = <10000 9800 9600 9400 9200 9000>,
			<8800 8600 8400 8200 8000 7800>,
			<7600 7400 7200 7000 6800 6600>,
			<6400 6200 6000 5800 5600 5400>,
			<5200 5000 4800 4600 4400 4200>,
			<4000 3800 3600 3400 3200 3000>,
			<2800 2600 2400 2200 2000 1800>,
			<1600 1400 1200 1000 900 800>,
			<700 600 500 400 300 200>,
			<100 0>;
		qcom,lut-data = <16535 16545 16526 16472 16463 16466>,
			<16598 16555 16542 16473 16466 16471>,
			<16667 16574 16556 16475 16469 16477>,
			<16733 16595 16566 16476 16473 16485>,
			<16790 16613 16572 16478 16476 16491>,
			<16829 16621 16574 16479 16478 16493>,
			<16851 16621 16571 16479 16478 16494>,
			<16867 16622 16566 16480 16478 16495>,
			<16875 16623 16561 16481 16478 16494>,
			<16879 16624 16557 16483 16478 16492>,
			<16883 16627 16555 16485 16479 16491>,
			<16890 16636 16557 16489 16480 16490>,
			<16897 16652 16561 16494 16481 16489>,
			<16900 16669 16569 16500 16484 16490>,
			<16894 16690 16583 16509 16487 16491>,
			<16884 16709 16601 16519 16491 16493>,
			<16866 16728 16627 16532 16496 16496>,
			<16835 16743 16654 16548 16502 16500>,
			<16803 16738 16680 16577 16515 16507>,
			<16770 16696 16704 16616 16538 16520>,
			<16737 16648 16704 16628 16552 16534>,
			<16708 16605 16642 16598 16558 16555>,
			<16682 16566 16570 16555 16561 16570>,
			<16659 16546 16532 16518 16542 16550>,
			<16642 16535 16505 16481 16490 16498>,
			<16626 16528 16496 16471 16471 16478>,
			<16610 16524 16493 16473 16472 16474>,
			<16593 16521 16492 16476 16473 16473>,
			<16584 16520 16493 16481 16477 16475>,
			<16589 16520 16496 16488 16487 16480>,
			<16601 16519 16500 16496 16496 16488>,
			<16609 16516 16505 16503 16509 16499>,
			<16614 16512 16509 16510 16518 16511>,
			<16619 16512 16511 16520 16522 16521>,
			<16627 16513 16511 16529 16524 16529>,
			<16635 16515 16511 16530 16523 16529>,
			<16641 16525 16512 16523 16513 16517>,
			<16647 16539 16514 16513 16503 16508>,
			<16651 16550 16517 16502 16499 16510>,
			<16653 16560 16520 16491 16497 16515>,
			<16654 16565 16520 16490 16498 16521>,
			<16655 16557 16517 16495 16506 16528>,
			<16656 16550 16510 16488 16499 16512>,
			<16657 16550 16502 16467 16460 16463>,
			<16667 16558 16494 16464 16454 16457>,
			<16682 16567 16506 16480 16482 16503>,
			<16684 16584 16523 16503 16520 16547>,
			<16672 16598 16549 16537 16561 16589>,
			<16683 16620 16591 16574 16598 16623>,
			<16820 16677 16645 16575 16606 16617>,
			<17154 17058 16708 16513 16519 16521>,
			<18040 18888 16859 16496 16492 16495>,
			<21279 31273 18481 16504 16489 16495>,
			<27674 30245 34598 16532 16487 16492>,
			<27674 30245 34598 16532 16487 16492>,
			<27674 30245 34598 16532 16487 16492>;
	};

	qcom,pc-temp-y5-lut {
		qcom,lut-col-legend = <(-10) 0 10 25 40 50>;
		qcom,lut-row-legend = <10000 9800 9600 9400 9200 9000>,
			<8800 8600 8400 8200 8000 7800>,
			<7600 7400 7200 7000 6800 6600>,
			<6400 6200 6000 5800 5600 5400>,
			<5200 5000 4800 4600 4400 4200>,
			<4000 3800 3600 3400 3200 3000>,
			<2800 2600 2400 2200 2000 1800>,
			<1600 1400 1200 1000 900 800>,
			<700 600 500 400 300 200>,
			<100 0>;
		qcom,lut-data = <16519 21328 21622 22021 22955 20469>,
			<16993 21312 21616 21999 22890 21119>,
			<17545 21231 21598 21862 22758 21826>,
			<18094 21100 21571 21629 22586 22471>,
			<18559 20934 21536 21317 22402 22935>,
			<18859 20743 21495 20947 22230 23099>,
			<18990 20475 21280 20474 22062 22980>,
			<19075 20083 20916 19940 21851 22788>,
			<19183 19549 20587 19428 21543 22558>,
			<19308 18723 20149 18849 21076 21929>,
			<19479 17984 19646 18270 20543 21386>,
			<19801 17412 18975 17546 19938 20599>,
			<20316 16983 18236 16763 19279 19646>,
			<20848 16956 17496 16157 18624 19088>,
			<21509 17253 16616 15644 17949 18685>,
			<22018 17757 16152 15226 17360 18370>,
			<22110 19438 16111 14821 16849 17994>,
			<22140 21770 16232 14557 16429 17638>,
			<22182 22810 17485 14627 16113 17222>,
			<22288 23379 20354 15018 15824 16462>,
			<22421 23608 22381 15873 15826 16258>,
			<22527 23540 23687 19988 18239 18045>,
			<22635 23396 24481 23731 21139 20251>,
			<22679 23249 24614 23722 22160 21396>,
			<22269 23076 24605 23076 22811 22245>,
			<21610 22953 24625 22415 22848 22459>,
			<21409 23068 24409 21740 20451 22357>,
			<21757 23265 24004 21032 17785 22145>,
			<21905 23362 23584 20214 16905 20859>,
			<19479 23752 23557 19409 16370 18300>,
			<15384 24115 24091 19182 16254 17006>,
			<14118 24339 24867 19177 16407 16408>,
			<13946 24537 25127 19209 16699 16141>,
			<13875 24503 25081 19678 17499 17574>,
			<13899 24254 25041 20705 18949 20237>,
			<13981 24101 25056 21825 20040 20874>,
			<14123 24149 25424 23346 20826 20737>,
			<14543 24207 25824 24218 21455 20623>,
			<14904 24183 25595 23340 22049 21231>,
			<14836 24119 25109 21881 22568 22222>,
			<14545 24084 24833 21719 22620 22307>,
			<14238 23003 24734 22310 22125 21632>,
			<13901 20965 23811 21922 21688 21312>,
			<13705 16616 23372 19999 21206 21244>,
			<13735 14355 20041 18827 19940 20102>,
			<13564 13796 16835 18699 18296 15953>,
			<13419 13393 16407 19620 16777 14793>,
			<13503 13739 16934 19151 15762 14280>,
			<13515 13881 17063 18602 15501 14210>,
			<11972 13444 16952 18425 15349 14264>,
			<10673 11223 16107 18922 15535 14786>,
			<9933 9658 14485 19421 16295 15994>,
			<9607 9165 12325 19891 16471 15048>,
			<9950 14462 10700 22156 17665 16872>,
			<9950 14462 10700 22156 17665 16872>,
			<9950 14462 10700 22156 17665 16872>;
	};

	qcom,pc-temp-y6-lut {
		qcom,lut-col-legend = <(-10) 0 10 25 40 50>;
		qcom,lut-row-legend = <10000 9800 9600 9400 9200 9000>,
			<8800 8600 8400 8200 8000 7800>,
			<7600 7400 7200 7000 6800 6600>,
			<6400 6200 6000 5800 5600 5400>,
			<5200 5000 4800 4600 4400 4200>,
			<4000 3800 3600 3400 3200 3000>,
			<2800 2600 2400 2200 2000 1800>,
			<1600 1400 1200 1000 900 800>,
			<700 600 500 400 300 200>,
			<100 0>;
		qcom,lut-data = <5554 5254 5173 5025 4990 4981>,
			<5560 5255 5171 5025 4992 4984>,
			<5565 5256 5169 5025 4994 4987>,
			<5569 5255 5166 5025 4996 4991>,
			<5572 5254 5162 5025 4998 4994>,
			<5573 5253 5158 5025 4999 4996>,
			<5572 5250 5154 5026 5000 4997>,
			<5570 5246 5149 5026 5001 4997>,
			<5568 5242 5145 5027 5001 4998>,
			<5565 5238 5141 5027 5002 4998>,
			<5562 5237 5138 5028 5003 4998>,
			<5560 5237 5137 5029 5003 4998>,
			<5559 5238 5136 5031 5004 4998>,
			<5556 5240 5136 5033 5005 4999>,
			<5552 5243 5138 5035 5007 5000>,
			<5545 5248 5141 5038 5008 5001>,
			<5536 5253 5145 5042 5010 5003>,
			<5523 5258 5152 5047 5013 5005>,
			<5510 5256 5159 5054 5018 5008>,
			<5498 5241 5166 5063 5025 5012>,
			<5487 5224 5166 5066 5028 5016>,
			<5478 5210 5145 5056 5027 5019>,
			<5470 5198 5121 5042 5024 5020>,
			<5465 5192 5109 5030 5016 5013>,
			<5462 5189 5101 5018 4999 4994>,
			<5461 5188 5098 5015 4993 4988>,
			<5461 5188 5097 5015 4992 4988>,
			<5462 5189 5097 5017 4992 4988>,
			<5464 5190 5097 5018 4993 4989>,
			<5466 5193 5099 5020 4996 4990>,
			<5470 5195 5102 5023 4999 4991>,
			<5476 5197 5104 5025 5002 4994>,
			<5488 5200 5107 5028 5005 4997>,
			<5503 5203 5109 5032 5008 5001>,
			<5520 5208 5110 5036 5009 5005>,
			<5543 5214 5112 5036 5010 5006>,
			<5569 5224 5114 5035 5006 5001>,
			<5601 5237 5118 5033 5003 4997>,
			<5637 5252 5122 5031 5003 4998>,
			<5676 5270 5126 5027 5004 5001>,
			<5719 5291 5131 5028 5004 5003>,
			<5771 5311 5137 5031 5007 5005>,
			<5835 5335 5143 5029 5005 5000>,
			<5924 5367 5152 5023 4992 4984>,
			<6069 5421 5159 5024 4993 4986>,
			<6299 5505 5182 5034 5006 5003>,
			<6447 5592 5207 5045 5019 5017>,
			<6631 5731 5250 5057 5032 5031>,
			<7023 6006 5313 5069 5043 5042>,
			<7987 6819 5418 5069 5045 5040>,
			<10024 9217 5623 5049 5017 5011>,
			<14899 16226 6256 5048 5011 5007>,
			<28441 44335 9070 5057 5015 5010>,
			<65535 65535 22026 5079 5020 5015>,
			<65535 65535 22026 5079 5020 5015>,
			<65535 65535 22026 5079 5020 5015>;
	};

};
